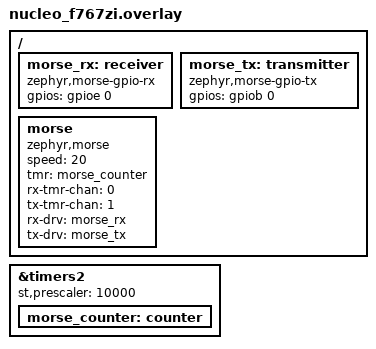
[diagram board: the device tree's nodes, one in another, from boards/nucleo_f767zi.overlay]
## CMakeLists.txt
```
# SPDX-License-Identifier: Apache-2.0

cmake_minimum_required(VERSION 3.20.0)
find_package(Zephyr REQUIRED HINTS $ENV{ZEPHYR_BASE})
project(morse_code)

FILE(GLOB app_sources src/*.c)
target_sources(app PRIVATE ${app_sources})
```

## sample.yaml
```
sample:
  name: Morse Code Sample
tests:
  sample.subsys.morse.morse_code:
    tags:
      - morse
    platform_allow:
      - nrf52840dk/nrf52840
      - nucleo_f767zi
      - nucleo_g474re
      - nucleo_h753zi
      - sam_v71_xult/samv71q21
      - sam4e_xpro
```

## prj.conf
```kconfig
CONFIG_LOG=y

CONFIG_COUNTER=y
CONFIG_GPIO=y
CONFIG_MORSE=y
CONFIG_MORSE_LOG_LEVEL_DBG=y

CONFIG_SHELL=y
CONFIG_MORSE_SHELL=y
```

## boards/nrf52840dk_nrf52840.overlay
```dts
/*
 * Copyright (c) 2024-2026 Freedom Veiculos Eletricos
 * Copyright (c) 2024-2026 O.S. Systems Software LTDA.
 *
 * SPDX-License-Identifier: Apache-2.0
 */

/ {
	morse_rx: receiver {
		compatible = "zephyr,morse-gpio-rx";

		gpios = <&gpio1 3 (GPIO_PULL_DOWN | GPIO_ACTIVE_HIGH)>;
	};

	morse_tx: transmitter {
		compatible = "zephyr,morse-gpio-tx";

		gpios = <&gpio1 4 GPIO_ACTIVE_HIGH>;
	};

	morse: morse {
		compatible = "zephyr,morse";
		status = "okay";

		speed = <20>;

		tmr = <&timer0>;

		tx-tmr-chan = <0>;
		rx-tmr-chan = <1>;

		tx-drv = <&morse_tx>;
		rx-drv = <&morse_rx>;
	};
};

&timer0 {
	status = "okay";
	prescaler = <8>;
};
```

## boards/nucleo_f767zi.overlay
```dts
/*
 * Copyright (c) 2024-2026 Freedom Veiculos Eletricos
 * Copyright (c) 2024-2026 O.S. Systems Software LTDA.
 *
 * SPDX-License-Identifier: Apache-2.0
 */

/ {
	/* zio.d34 */
	morse_rx: receiver {
		compatible = "zephyr,morse-gpio-rx";

		gpios = <&gpioe 0 GPIO_ACTIVE_HIGH>;
	};

	/* zio.d33 */
	morse_tx: transmitter {
		compatible = "zephyr,morse-gpio-tx";

		gpios = <&gpiob 0 GPIO_ACTIVE_HIGH>;
	};

	morse: morse {
		compatible = "zephyr,morse";
		status = "okay";

		speed = <20>;
		tmr = <&morse_counter>;

		rx-tmr-chan = <0>;
		tx-tmr-chan = <1>;

		rx-drv = <&morse_rx>;
		tx-drv = <&morse_tx>;
	};
};

&timers2 {
	st,prescaler = <10000>;
	status = "okay";

	morse_counter: counter {
		status = "okay";
	};
};
```

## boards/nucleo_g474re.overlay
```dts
/*
 * Copyright (c) 2024-2026 Freedom Veiculos Eletricos
 * Copyright (c) 2024-2026 O.S. Systems Software LTDA.
 *
 * SPDX-License-Identifier: Apache-2.0
 */

/ {
	/* arduino.pd12 */
	morse_rx: receiver {
		compatible = "zephyr,morse-gpio-rx";

		gpios = <&gpioa 6 GPIO_ACTIVE_HIGH>;
	};

	/* arduino.pd13 */
	morse_tx: transmitter {
		compatible = "zephyr,morse-gpio-tx";

		gpios = <&gpioa 5 GPIO_ACTIVE_HIGH>;
	};

	morse: morse {
		compatible = "zephyr,morse";
		status = "okay";

		speed = <20>;
		tmr = <&morse_counter>;

		rx-tmr-chan = <0>;
		tx-tmr-chan = <1>;

		rx-drv = <&morse_rx>;
		tx-drv = <&morse_tx>;
	};
};

&timers2 {
	st,prescaler = <10000>;
	status = "okay";

	morse_counter: counter {
		status = "okay";
	};
};
```

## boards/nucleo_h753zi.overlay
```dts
/*
 * Copyright (c) 2024-2026 Freedom Veiculos Eletricos
 * Copyright (c) 2024-2026 O.S. Systems Software LTDA.
 *
 * SPDX-License-Identifier: Apache-2.0
 */

/ {
	/* zio.d33 */
	morse_tx: transmitter {
		compatible = "zephyr,morse-pwm-tx";

		pwms = <&pwm12 1 PWM_MSEC(80) PWM_POLARITY_NORMAL>;
	};

	morse: morse {
		compatible = "zephyr,morse";
		status = "okay";

		speed = <2>;
		tmr = <&morse_counter>;

		tx-tmr-chan = <0>;

		tx-drv = <&morse_tx>;
	};
};

&timers2 {
	st,prescaler = <10000>;
	status = "okay";

	morse_counter: counter {
		status = "okay";
	};
};
```

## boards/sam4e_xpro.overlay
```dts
/*
 * Copyright (c) 2024-2026 Freedom Veiculos Eletricos
 * Copyright (c) 2024-2026 O.S. Systems Software LTDA.
 *
 * SPDX-License-Identifier: Apache-2.0
 */

/ {
	morse_rx: receiver {
		compatible = "zephyr,morse-gpio-rx";

		gpios = <&piod 22 GPIO_ACTIVE_LOW>;
	};

	morse_tx: transmitter {
		compatible = "zephyr,morse-gpio-tx";

		gpios = <&piod 22 GPIO_ACTIVE_LOW>;
	};

	morse: morse {
		compatible = "zephyr,morse";
		status = "okay";

		speed = <20>;

		tmr = <&tc0>;
		tx-tmr-chan = <1>;
		rx-tmr-chan = <0>;

		tx-drv = <&morse_tx>;
		rx-drv = <&morse_rx>;
	};
};

&tc0 {
	clk = <4>;
	status = "okay";
};
```

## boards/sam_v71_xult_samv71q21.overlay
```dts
/*
 * Copyright (c) 2024-2026 Freedom Veiculos Eletricos
 * Copyright (c) 2024-2026 O.S. Systems Software LTDA.
 *
 * SPDX-License-Identifier: Apache-2.0
 */

/ {
	morse_rx: receiver {
		compatible = "zephyr,morse-gpio-rx";

		gpios = <&pioc 9 GPIO_ACTIVE_LOW>;
	};

	morse_tx: transmitter {
		compatible = "zephyr,morse-gpio-tx";

		gpios = <&pioc 9 GPIO_ACTIVE_LOW>;
	};

	morse: morse {
		compatible = "zephyr,morse";
		status = "okay";

		speed = <20>;

		tmr = <&tc0>;
		tx-tmr-chan = <0>;
		rx-tmr-chan = <1>;

		tx-drv = <&morse_tx>;
		rx-drv = <&morse_rx>;
	};
};

&tc0 {
	clk = <4>;
	status = "okay";
};
```

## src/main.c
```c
/*
 * Copyright (c) 2024-2026 Freedom Veiculos Eletricos
 * Copyright (c) 2024-2026 O.S. Systems Software LTDA.
 *
 * SPDX-License-Identifier: Apache-2.0
 */

#include <zephyr/kernel.h>
#include <zephyr/device.h>

#include <zephyr/morse/morse.h>

#include <zephyr/logging/log.h>
LOG_MODULE_REGISTER(app, CONFIG_MORSE_LOG_LEVEL);

/**
 * @file Send data using morse code.
 */

const uint8_t tx_data[] = "paris";
uint8_t rx_data[sizeof(tx_data)] = {};
int rx_counter;

void morse_tx_cb_handler(void *ctx, int status)
{
	LOG_INF("TX status: %d", status);
}

void morse_rx_cb_handler(void *ctx, enum morse_rx_state status, uint32_t data)
{
	LOG_DBG("RX status: %d, 0x%02x, '%c'", status, data, data);

	rx_data[rx_counter++] = data;

	if (status == MORSE_RX_STATE_END_TRANSMISSION) {
		rx_data[rx_counter++] = 0x00;
		LOG_INF("RX Data: %s", rx_data);
	}
}

int main(void)
{
	const struct device *const morse = DEVICE_DT_GET(DT_NODELABEL(morse));

	if (!device_is_ready(morse)) {
		return 0;
	}

	rx_counter = 0;
	morse_manage_callbacks(morse, morse_tx_cb_handler, morse_rx_cb_handler, NULL);
	morse_send(morse, tx_data, strlen(tx_data));

	return 0;
}
```
